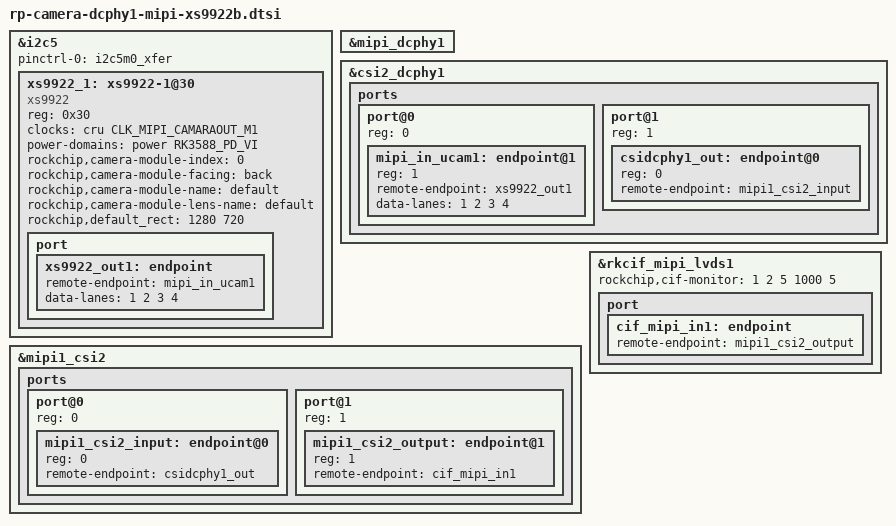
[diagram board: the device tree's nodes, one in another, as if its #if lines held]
/*
 * xs9922_1 -> mipi_dcphy1 -> mipi1_csi2 -> cif1 -> rkisp1_vir0
 */

#ifdef RD_RK3588_VIDEO
&i2c5 {
    status = "okay";
    pinctrl-names = "default";
    pinctrl-0 = <&i2c5m0_xfer>;
        
    xs9922_1: xs9922-1@30 {
        compatible = "xs9922";
        status = "okay";
        reg = <0x30>;
        clocks = <&cru CLK_MIPI_CAMARAOUT_M1>;
        clock-names = "xvclk";
        power-domains = <&power RK3588_PD_VI>;
        // pinctrl-names = "default";
        // pinctrl-0 = <&xs9922_pwr_1>;
        // power-gpios = <&gpio2 RK_PB7 GPIO_ACTIVE_HIGH>;
        //avdd-supply = <&vcc_avdd>;
        //dovdd-supply = <&vcc_dovdd>;
        //dvdd-supply = <&vcc_dvdd>;
        rockchip,camera-module-index = <0>;
        rockchip,camera-module-facing = "back";
        rockchip,camera-module-name = "default";
        rockchip,camera-module-lens-name = "default";
        rockchip,default_rect= <1280 720>; 
        port {
            xs9922_out1: endpoint {
                remote-endpoint = <&mipi_in_ucam1>;
                data-lanes = <1 2 3 4>;
            };
        };
    };
};
#else
&i2c2 {
    status = "okay";
    pinctrl-names = "default";
    pinctrl-0 = <&i2c2m4_xfer>;
    
    xs9922_1: xs9922@30 {
        compatible = "xs9922";
        status = "okay";
        reg = <0x30>;
        clocks = <&cru CLK_MIPI_CAMARAOUT_M1>;
        clock-names = "xvclk";
        power-domains = <&power RK3588_PD_VI>;
        pinctrl-names = "default";
        pinctrl-0 = <&xs9922_pwr_1>;
        reset-gpios = <&gpio4 RK_PA5 GPIO_ACTIVE_HIGH>;
        power-gpios = <&gpio1 RK_PD5 GPIO_ACTIVE_HIGH>;
        //avdd-supply = <&vcc_avdd>;
        //dovdd-supply = <&vcc_dovdd>;
        //dvdd-supply = <&vcc_dvdd>;
        rockchip,camera-module-index = <0>;
        rockchip,camera-module-facing = "back";
        rockchip,camera-module-name = "default";
        rockchip,camera-module-lens-name = "default";
        rockchip,default_rect= <1280 720>; 
        port {
            xs9922_out1: endpoint {
                remote-endpoint = <&mipi_in_ucam1>;
                data-lanes = <1 2 3 4>;
            };
        };
    };
};

&pinctrl {
    xs9922 {
        xs9922_pwr_1: camera-pwr_1 {
            rockchip,pins =
            <1 RK_PD5 RK_FUNC_GPIO &pcfg_pull_none>,
            <4 RK_PA5 RK_FUNC_GPIO &pcfg_pull_none>;
        };
    };
};
#endif //end define RD-RK3588-VIDEO

&mipi_dcphy1 {
    status = "okay";
};

&csi2_dcphy1 {
    status = "okay";

    ports {
        #address-cells = <1>;
        #size-cells = <0>;
        port@0 {
            reg = <0>;
            #address-cells = <1>;
            #size-cells = <0>;

            mipi_in_ucam1: endpoint@1 {
                reg = <1>;
                remote-endpoint = <&xs9922_out1>;
                data-lanes = <1 2 3 4>;
            };
        };

        port@1 {
            reg = <1>;
            #address-cells = <1>;
            #size-cells = <0>;

            csidcphy1_out: endpoint@0 {
                reg = <0>;
                remote-endpoint = <&mipi1_csi2_input>;
            };
        };
    };
};

&mipi1_csi2 {
    status = "okay";

    ports {
        #address-cells = <1>;
        #size-cells = <0>;

        port@0 {
            reg = <0>;
            #address-cells = <1>;
            #size-cells = <0>;

            mipi1_csi2_input: endpoint@0 {
                reg = <0>;
                remote-endpoint = <&csidcphy1_out>;
            };
        };

        port@1 {
            reg = <1>;
            #address-cells = <1>;
            #size-cells = <0>;

            mipi1_csi2_output: endpoint@1 {
                reg = <1>;
                remote-endpoint = <&cif_mipi_in1>;
            };
        };
    };
};

&rkcif_mipi_lvds1 {
    status = "okay";
    rockchip,cif-monitor = <1 2 5 1000 5>;
    port {
        cif_mipi_in1: endpoint {
            remote-endpoint = <&mipi1_csi2_output>;
        };
    };
};

#if 0
&rkcif_mipi_lvds1_sditf {
    status = "okay";

    port {
        mipi_lvds1_sditf: endpoint {
            remote-endpoint = <&isp0_vir1>;
        };
    };
};

&rkisp0 {
    status = "okay";
};

&isp0_mmu {
    status = "okay";
};

&rkisp0_vir1 {
    status = "okay";
    port {
        #address-cells = <1>;
        #size-cells = <0>;

        isp0_vir1: endpoint@0 {
            reg = <0>;
            remote-endpoint = <&mipi_lvds1_sditf>;
        };
    };
};
#endif

